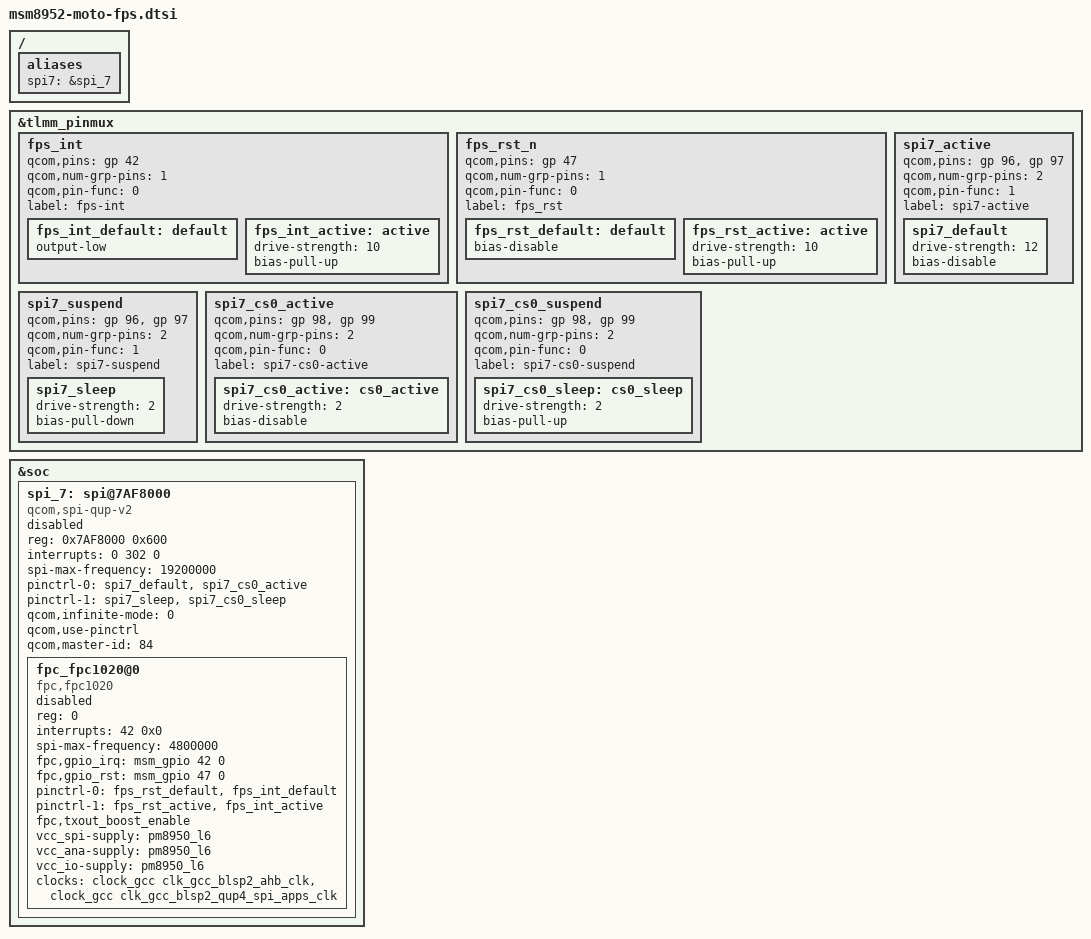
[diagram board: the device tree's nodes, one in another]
/* Copyright (c) 2015, Motorola Mobility Inc. All rights reserved.
 *
 * This program is free software; you can redistribute it and/or modify
 * it under the terms of the GNU General Public License version 2 and
 * only version 2 as published by the Free Software Foundation.
 *
 * This program is distributed in the hope that it will be useful,
 * but WITHOUT ANY WARRANTY; without even the implied warranty of
 * MERCHANTABILITY or FITNESS FOR A PARTICULAR PURPOSE.  See the
 * GNU General Public License for more details.
 */

/ {
	aliases {
		spi7 = &spi_7;
	};
};

&tlmm_pinmux {
	fps_int {
		qcom,pins = <&gp 42>;
		qcom,num-grp-pins = <1>;
		qcom,pin-func = <0>;
		label = "fps-int";

		fps_int_default: default {
			output-low;
		};

		fps_int_active: active {
			drive-strength = <10>;
			bias-pull-up; /* pull-up */
		};
	};

	fps_rst_n {
		qcom,pins = <&gp 47>;
		qcom,num-grp-pins = <1>;
		qcom,pin-func = <0>;
		label = "fps_rst";

		fps_rst_default: default {
			bias-disable;
		};

		fps_rst_active: active {
			drive-strength = <10>;
			bias-pull-up; /* pull-up */
		};
	};

	spi7_active {
		/* BLSP8 MOSI, MISO */
		qcom,pins = <&gp 96>, <&gp 97>;
		qcom,num-grp-pins = <2>;
		qcom,pin-func = <1>;
		label = "spi7-active";
		/* active state */
		spi7_default: spi7_default {
			drive-strength = <12>; /* 12 MA */
			bias-disable; /* No PULL */
		};
	};

	spi7_suspend {
		/* BLSP8 MOSI, MISO */
		qcom,pins = <&gp 96>, <&gp 97>;
		qcom,num-grp-pins = <2>;
		qcom,pin-func = <1>;
		label = "spi7-suspend";
		/* suspended state */
		spi7_sleep: spi7_sleep {
			drive-strength = <2>; /* 2 MA */
			bias-pull-down; /* PULL Down */
		};
	};

	spi7_cs0_active {
		/* BLSP8 CS, CLK */
		qcom,pins = <&gp 98>, <&gp 99>;
		qcom,num-grp-pins = <2>;
		qcom,pin-func = <0>;
		label = "spi7-cs0-active";
		spi7_cs0_active: cs0_active {
			drive-strength = <2>;
			bias-disable;
		};
	};

	spi7_cs0_suspend {
		/* BLSP8 CS, CLK */
		qcom,pins = <&gp 98>, <&gp 99>;
		qcom,num-grp-pins = <2>;
		qcom,pin-func = <0>;
		label = "spi7-cs0-suspend";
		spi7_cs0_sleep: cs0_sleep {
			drive-strength = <2>;
			bias-pull-up;
		};
	};
};

&soc {
	spi_7: spi@7AF8000 {
		compatible = "qcom,spi-qup-v2";
		#address-cells = <1>;
		#size-cells = <0>;
		reg-names = "spi_physical";
		reg = <0x7AF8000 0x600>;
		interrupt-names = "spi_irq";
		interrupts = <0 302 0>;
		spi-max-frequency = <19200000>;
		pinctrl-names = "spi_default", "spi_sleep";
		pinctrl-0 = <&spi7_default &spi7_cs0_active>;
		pinctrl-1 = <&spi7_sleep &spi7_cs0_sleep>;
		qcom,infinite-mode = <0>;
		qcom,use-pinctrl;
		qcom,master-id = <84>;
		status = "/chosen", "mmi,fps", "true";

		fpc_fpc1020@0{
			status = "/chosen", "mmi,fps", "true";
			compatible = "fpc,fpc1020";
			reg = <0>;
			interrupts = <42 0x0>;
			spi-max-frequency = <4800000>;
			fpc,gpio_irq = <&msm_gpio 42 0>;
			fpc,gpio_rst = <&msm_gpio 47 0>;
			pinctrl-names = "default", "active";
			pinctrl-0 = <&fps_rst_default &fps_int_default>;
			pinctrl-1 = <&fps_rst_active &fps_int_active>;
			fpc,txout_boost_enable;
			vcc_spi-supply = <&pm8950_l6>;
			vcc_ana-supply = <&pm8950_l6>;
			vcc_io-supply  = <&pm8950_l6>;
			clock-names = "iface_clk", "core_clk";
			clocks = <&clock_gcc clk_gcc_blsp2_ahb_clk>,
				<&clock_gcc clk_gcc_blsp2_qup4_spi_apps_clk>;
		};
	};
};
